# nrf54l15_enga_application register map
Vendor: Nordic Semiconductor; Series: nrf54l; File version: 1
CPU: CM33 r0p4, little endian, MPU, FPU, 3 interrupt priority bits, 270 interrupts, 4 SAU regions
Registers are 32-bit, read-write, reset 0x0 unless marked. A register's access mark holds for its fields unless they carry their own. Offsets are from the block's base; [hi:lo] are bit positions; {n}, {i} and the like mark numbered series; 'fields as' and 'values as' point back to an identical list.

## GLOBAL_SREGS00_NS — Spare registers 0
Base 0x40056000
Same registers: GLOBAL_SREGS10_NS 0x4008C000, GLOBAL_SREGS20_NS 0x400E6000, GLOBAL_SREGS30_NS 0x4010F000, GLOBAL_SREGS00_S 0x50056000, GLOBAL_SREGS10_S 0x5008C000, GLOBAL_SREGS20_S 0x500E6000, GLOBAL_SREGS30_S 0x5010F000
{0x500+4i} REG[{i}] (i=0..1) — Description collection: Spare register n
  [31:0] VALUE
0x580 TESTREG — Test special register
  [3:0] TESTFIELD
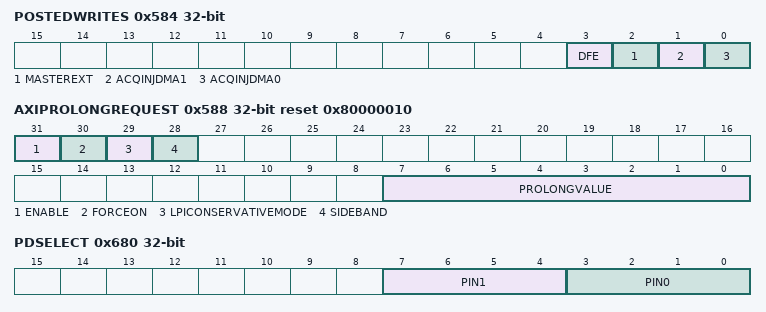
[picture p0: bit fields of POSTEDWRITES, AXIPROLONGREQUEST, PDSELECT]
0x584 POSTEDWRITES — Enable or disable posted writes functionality for specific AXI/AHB bus masters
  [all] fields
    0=Disabled (Disable posted writes); 1=Enabled (Enable posted writes)
  [3] DFE — Disable or enable posted writes for Radio AHB for Direction Finding
  [2] MASTEREXT — Disable or enable posted writes for Radio AHB for Radio packets
  [1] ACQINJDMA1 — Disable or enable posted writes for Radio ACQINJDMA1
  [0] ACQINJDMA0 — Disable or enable posted writes for Radio ACQINJDMA0
0x588 AXIPROLONGREQUEST reset 0x80000010 — Configuration of the AxiRequestProlonger module.
  [31] ENABLE — Disable or enable the prolong functionality
    0=Disabled (Disable prolong functionality); 1=Enabled (Enable prolong functionality)
  [30] FORCEON — Disable or enable constant prolong request
    0=Disabled (Disable FORCEON); 1=Enabled (Enable FORCEON)
  [29] LPICONSERVATIVEMODE — Disable or enable LPI conservative mode
    values as the fields of POSTEDWRITES
  [28] SIDEBAND — Disable or enable additional sideband request
    0=Disabled (Disable sideband); 1=Enabled (Enable sideband)
  [7:0] PROLONGVALUE — Number of additional clocks the request is prolonged
0x58C RADIOSIDEBANDREQUEST — Sideband request from Radio to LRC.
  [0] SIDEBAND — Disable or enable sideband request for Radio
    0=Disabled (Disable sideband request); 1=Enabled (Enable sideband request)
{0x600+4i} MAINREG[{i}] (i=0..0) — Description collection: Spare register n in PD_MAIN
  [7:0] VALUE
0x680 PDSELECT — Power domain status selection
  [7:4] PIN1 — Mapping for pin P0.04
    0=Disable (pin is used as regular pin); 1=PdMain (Shows if PD_MAIN is on); 2=PdLp (Shows if PD_LP is on); 3=PdPeri (Shows if PD_M (also called PD_PERI) is on); 4=PdMcu (Shows if PD_MCU is on); 5=PdRadio (Shows if PD_RADIO is on); 6=PdCracen (Shows if PD_AUX (also called PD_CRACEN) is on); 7=PwrAboveElv (Not in Elv mode (pwrAboveElv_a)); 8=VREGMAIN in Ext mode; 9=VREGMAIN in Ldo mode; 10=VREGMAIN in Pfm mode; 11=VREGMAIN in PWm mode
  [3:0] PIN0 — Mapping for pin P0.03
    values as PIN1
{0x700+4i} AOREG[{i}] (i=0..0) — Description collection: Spare register n in PD_AO
  [3:0] VALUE
0x704 AODFT — AO control of DFT features
  [0] DTBENABLE — Output DTB on GPIO pins through Always-On pin muxing

## GLOBAL_SUPPORT00_S — PCGCSlave 0
Base 0x5005F000
Same registers: GLOBAL_SUPPORT10_S 0x5009E000, GLOBAL_SUPPORT20_S 0x500FF000, GLOBAL_PCGCS30_S 0x5011E000, GLOBAL_SUPPORT30_S 0x5011F000
{0xC00+4i} PENALTY[{i}] (i=0..1) — Description collection: Penalty level for power/clock pair n
  [7:0] PENALTY — Penalty level
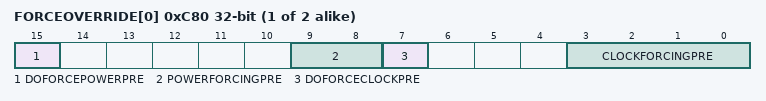
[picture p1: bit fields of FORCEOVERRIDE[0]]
{0xC80+4i} FORCEOVERRIDE[{i}] (i=0..1) — Description collection: Force override of power/clock pair n
  [15] DOFORCEPOWERPRE, [9:8] POWERFORCINGPRE, [7] DOFORCECLOCKPRE, [3:0] CLOCKFORCINGPRE

## GLOBAL_EGU10_NS — Event generator unit 0
Base 0x40087000
Same registers: GLOBAL_EGU20_NS 0x400C9000, GLOBAL_EGU10_S 0x50087000, GLOBAL_EGU20_S 0x500C9000
{0x0+4i} TASKS_TRIGGER[{i}] (i=0..15) wo — Description collection: Trigger n for triggering the corresponding TRIGGERED[n] event
  [0] TASKS_TRIGGER — Trigger n for triggering the corresponding TRIGGERED[n] event
    1=Trigger task
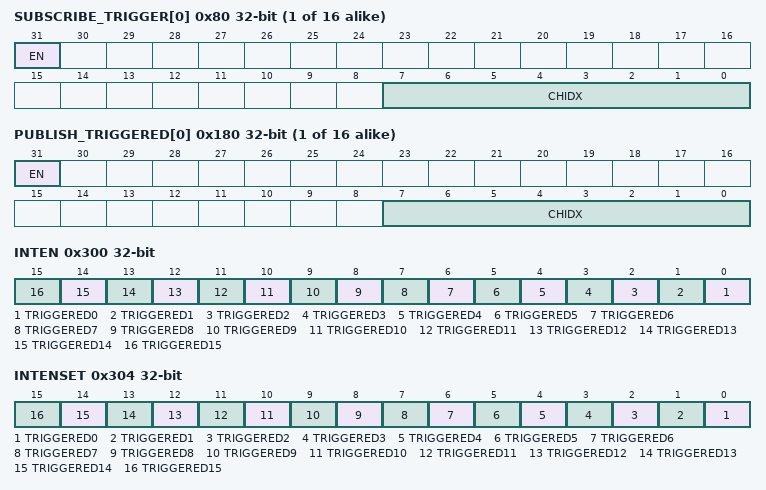
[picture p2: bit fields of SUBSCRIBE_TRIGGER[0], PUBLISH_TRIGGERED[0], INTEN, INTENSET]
{0x80+4i} SUBSCRIBE_TRIGGER[{i}] (i=0..15) — Description collection: Subscribe configuration for task TRIGGER[n]
  [31] EN
    0=Disabled (Disable subscription); 1=Enabled (Enable subscription)
  [7:0] CHIDX — DPPI channel that task TRIGGER[n] will subscribe to
{0x100+4i} EVENTS_TRIGGERED[{i}] (i=0..15) — Description collection: Event number n generated by triggering the corresponding TRIGGER[n] task
  [0] EVENTS_TRIGGERED — Event number n generated by triggering the corresponding TRIGGER[n] task
    0=NotGenerated (Event not generated); 1=Generated (Event generated)
{0x180+4i} PUBLISH_TRIGGERED[{i}] (i=0..15) — Description collection: Publish configuration for event TRIGGERED[n]
  [31] EN
    0=Disabled (Disable publishing); 1=Enabled (Enable publishing)
  [7:0] CHIDX — DPPI channel that event TRIGGERED[n] will publish to
0x300 INTEN — Enable or disable interrupt
  [all] fields
    0=Disabled; 1=Enabled
  [n] TRIGGERED{n} (n=0..15) — Enable or disable interrupt for event TRIGGERED[{n}]
0x304 INTENSET — Enable interrupt
  [all] fields
    on read: 0=Disabled (Read: Disabled); 1=Enabled (Read: Enabled) | on write: 1=Set (Enable)
  [n] TRIGGERED{n} (n=0..15) — Write '1' to enable interrupt for event TRIGGERED[{n}]
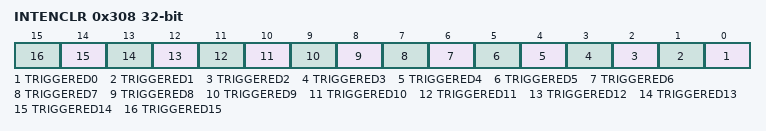
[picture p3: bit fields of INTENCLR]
0x308 INTENCLR — Disable interrupt
  [all] fields
    on read: 0=Disabled (Read: Disabled); 1=Enabled (Read: Enabled) | on write: 1=Clear (Disable)
  [n] TRIGGERED{n} (n=0..15) — Write '1' to disable interrupt for event TRIGGERED[{n}]
